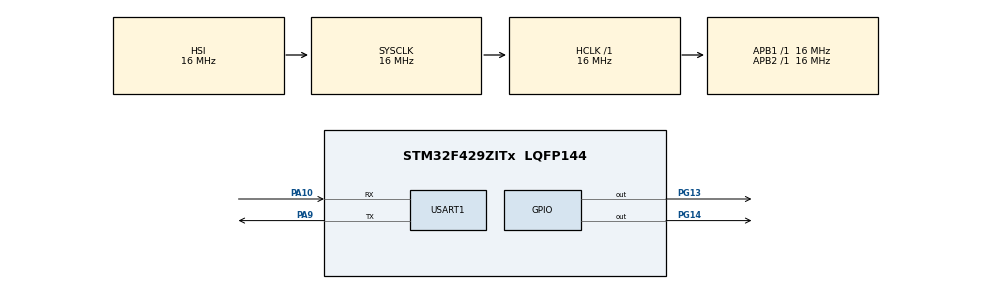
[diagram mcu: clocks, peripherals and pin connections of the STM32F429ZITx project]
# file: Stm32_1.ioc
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Mcu.Family=STM32F4
Mcu.Name=STM32F429ZITx
Mcu.Package=LQFP144
NVIC.PriorityGroup=NVIC_PRIORITYGROUP_4
PA10.Mode=Asynchronous
PA10.Signal=USART1_RX
PA13.Mode=Serial_Wire
PA13.Signal=SYS_JTMS-SWDIO
PA14.Mode=Serial_Wire
PA14.Signal=SYS_JTCK-SWCLK
PA9.Mode=Asynchronous
PA9.Signal=USART1_TX
PG13.Signal=GPIO_Output
PG14.Signal=GPIO_Output
PH0/OSC_IN.Mode=HSE-External-Oscillator
PH0/OSC_IN.Signal=RCC_OSC_IN
PH1/OSC_OUT.Mode=HSE-External-Oscillator
PH1/OSC_OUT.Signal=RCC_OSC_OUT
ProjectManager.HeapSize=0x200
ProjectManager.StackSize=0x400
ProjectManager.TargetToolchain=STM32CubeIDE
RCC.AHBFreq_Value=16000000
RCC.APB1Freq_Value=16000000
RCC.APB2Freq_Value=16000000
RCC.CortexFreq_Value=16000000
RCC.HSE_VALUE=25000000
RCC.HSI_VALUE=16000000
RCC.LSE_VALUE=32768
RCC.SYSCLKFreq_VALUE=16000000
RCC.VCOOutputFreq_Value=192000000
USART1.VirtualMode=VM_ASYNC
board=custom

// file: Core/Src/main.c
/* USER CODE BEGIN Header */
/**
  ******************************************************************************
  * @file           : main.c
  * @brief          : Main program body
  ******************************************************************************
  * @attention
  *
  * Copyright (c) 2025 STMicroelectronics.
  * All rights reserved.
  *
  * This software is licensed under terms that can be found in the LICENSE file
  * in the root directory of this software component.
  * If no LICENSE file comes with this software, it is provided AS-IS.
  *
  ******************************************************************************
  */
/* USER CODE END Header */
#include "main.h"

UART_HandleTypeDef huart1;

/* USER CODE BEGIN PV */
//uint8_t TX_Data[20] = {1,2,3,4,5,6,7,8,9,10,11,12,13,14,15,16,17,18,19,20};
int time=100;
/* USER CODE END PV */
uint8_t RX_Data;
uint8_t received_count = 0;
void SystemClock_Config(void);
static void MX_GPIO_Init(void);
static void MX_USART1_UART_Init(void);

int main(void)
{

  /* MCU Configuration--------------------------------------------------------*/

  /* Reset of all peripherals, Initializes the Flash interface and the Systick. */
  HAL_Init();

  /* Configure the system clock */
  SystemClock_Config();

  /* Initialize all configured peripherals */
  MX_GPIO_Init();
  MX_USART1_UART_Init();

  /* Infinite loop */
  /* USER CODE BEGIN WHILE */
//  while (1)
//  {
//	  // Gửi từng số nguyên qua UART
//	          for (uint8_t i = 0; i < 20; i++)
//	          {
//	              HAL_UART_Transmit(&huart1, &TX_Data[i], 1, 100);
//	              HAL_Delay(100); // Đợi để dữ liệu truyền ổn định
//	          }
//
//	          HAL_Delay(1000); // Đợi 1 giây trước khi gửi lại
//  }

  while (1)
  {
	  // Nhận dữ liệu từ UART
	          if (HAL_UART_Receive(&huart1, &RX_Data, 1, 100) == HAL_OK)
	          {
	              received_count++;
	              HAL_GPIO_TogglePin(GPIOG, GPIO_PIN_13); // Toggle LED4 mỗi lần nhận được dữ liệu
	              HAL_Delay(time);
	              time+=100;

	              // Khi nhận đủ 20 số, toggle LED3
	              if (received_count >= 20)
	              {
	                  HAL_GPIO_TogglePin(GPIOG, GPIO_PIN_14);
	                  received_count = 0; // Reset bộ đếm
	                  time=100;
	              }
	          }
  }
  /* USER CODE END 3 */
}

void SystemClock_Config(void)
{
  RCC_OscInitTypeDef RCC_OscInitStruct = {0};
  RCC_ClkInitTypeDef RCC_ClkInitStruct = {0};

  /** Configure the main internal regulator output voltage
  */
  __HAL_RCC_PWR_CLK_ENABLE();
  __HAL_PWR_VOLTAGESCALING_CONFIG(PWR_REGULATOR_VOLTAGE_SCALE3);

  /** Initializes the RCC Oscillators according to the specified parameters
  * in the RCC_OscInitTypeDef structure.
  */
  RCC_OscInitStruct.OscillatorType = RCC_OSCILLATORTYPE_HSI;
  RCC_OscInitStruct.HSIState = RCC_HSI_ON;
  RCC_OscInitStruct.HSICalibrationValue = RCC_HSICALIBRATION_DEFAULT;
  RCC_OscInitStruct.PLL.PLLState = RCC_PLL_NONE;
  if (HAL_RCC_OscConfig(&RCC_OscInitStruct) != HAL_OK)
  {
    Error_Handler();
  }

  /** Initializes the CPU, AHB and APB buses clocks
  */
  RCC_ClkInitStruct.ClockType = RCC_CLOCKTYPE_HCLK|RCC_CLOCKTYPE_SYSCLK
                              |RCC_CLOCKTYPE_PCLK1|RCC_CLOCKTYPE_PCLK2;
  RCC_ClkInitStruct.SYSCLKSource = RCC_SYSCLKSOURCE_HSI;
  RCC_ClkInitStruct.AHBCLKDivider = RCC_SYSCLK_DIV1;
  RCC_ClkInitStruct.APB1CLKDivider = RCC_HCLK_DIV1;
  RCC_ClkInitStruct.APB2CLKDivider = RCC_HCLK_DIV1;

  if (HAL_RCC_ClockConfig(&RCC_ClkInitStruct, FLASH_LATENCY_0) != HAL_OK)
  {
    Error_Handler();
  }
}

static void MX_USART1_UART_Init(void)
{

  huart1.Instance = USART1;
  huart1.Init.BaudRate = 115200;
  huart1.Init.WordLength = UART_WORDLENGTH_8B;
  huart1.Init.StopBits = UART_STOPBITS_1;
  huart1.Init.Parity = UART_PARITY_NONE;
  huart1.Init.Mode = UART_MODE_TX_RX;
  huart1.Init.HwFlowCtl = UART_HWCONTROL_NONE;
  huart1.Init.OverSampling = UART_OVERSAMPLING_16;
  if (HAL_UART_Init(&huart1) != HAL_OK)
  {
    Error_Handler();
  }

}

static void MX_GPIO_Init(void)
{
  GPIO_InitTypeDef GPIO_InitStruct = {0};

  /* GPIO Ports Clock Enable */
  __HAL_RCC_GPIOH_CLK_ENABLE();
  __HAL_RCC_GPIOA_CLK_ENABLE();
  __HAL_RCC_GPIOG_CLK_ENABLE();

  /*Configure GPIO pin Output Level */
  HAL_GPIO_WritePin(GPIOG, GPIO_PIN_13|GPIO_PIN_14, GPIO_PIN_RESET);

  /*Configure GPIO pins : PG13 PG14 */
  GPIO_InitStruct.Pin = GPIO_PIN_13|GPIO_PIN_14;
  GPIO_InitStruct.Mode = GPIO_MODE_OUTPUT_PP;
  GPIO_InitStruct.Pull = GPIO_NOPULL;
  GPIO_InitStruct.Speed = GPIO_SPEED_FREQ_LOW;
  HAL_GPIO_Init(GPIOG, &GPIO_InitStruct);

}

void Error_Handler(void)
{
  __disable_irq();
  while (1)
  {
  }
}
